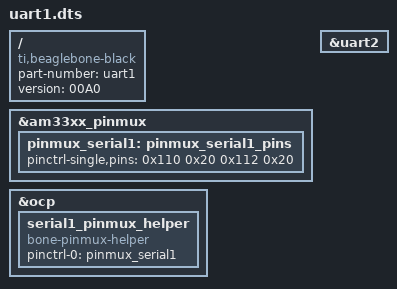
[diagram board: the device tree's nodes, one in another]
/dts-v1/;
/plugin/;

/{
   compatible = "ti,beaglebone-black";
   
   part-number = "uart1";
   version = "00A0";

   fragment@0 {
	target = <&am33xx_pinmux>;
	__overlay__ {
		pinmux_serial1: pinmux_serial1_pins {
		   pinctrl-single,pins= <
			0x110 0x20
			0x112 0x20
		   >;
		};
	};
   };

   fragment@1 {
	target = <&ocp>;
	__overlay__ {
		serial1_pinmux_helper {
		   compatible = "bone-pinmux-helper";
		   status = "okay";
		   pinctrl-names = "default";
		   pinctrl-0 = <&pinmux_serial1>;
		};
	};
   };

   fragment@2 {
	target = <&uart2>;
	__overlay__ {
		status = "okay";
	};
   };
};
